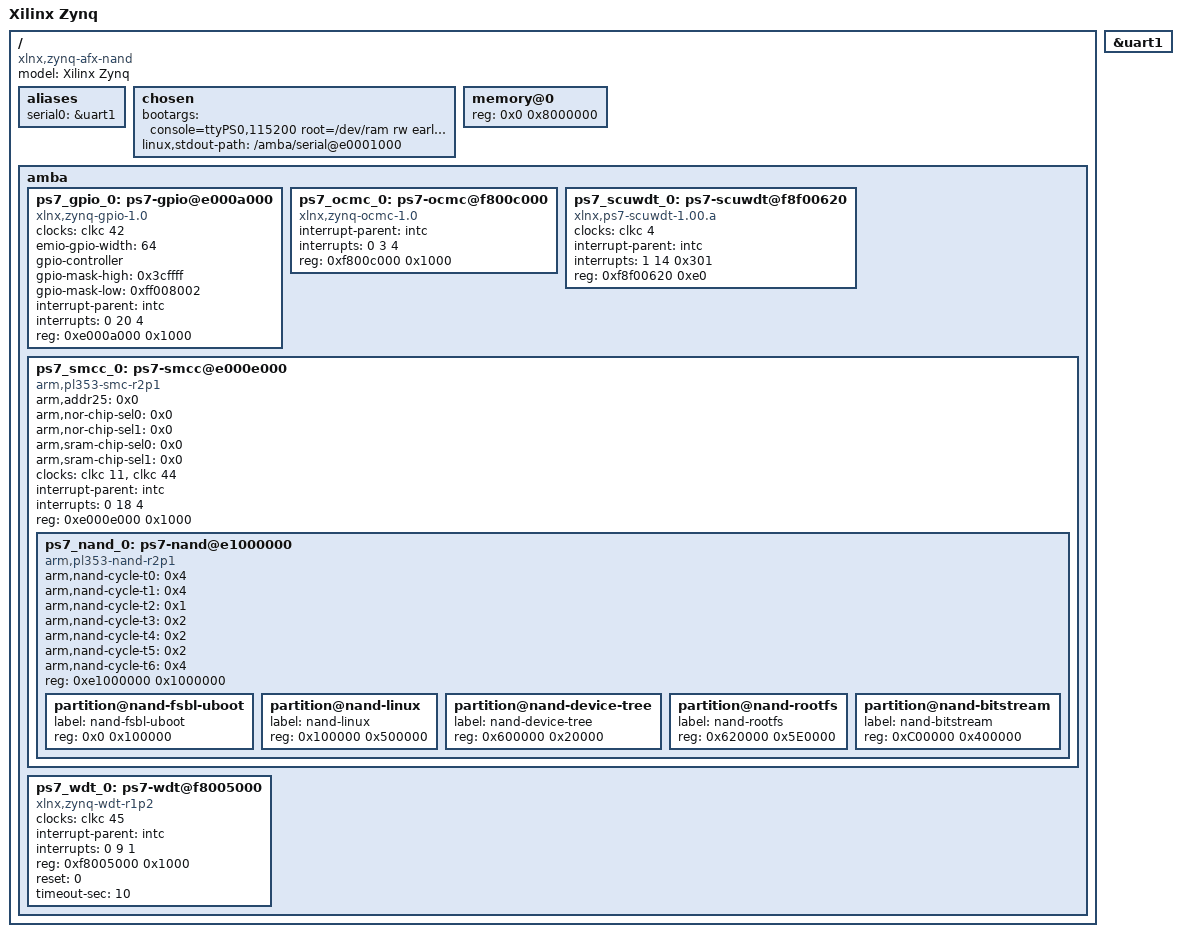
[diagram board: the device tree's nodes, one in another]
/*
 * Device Tree Generator version: 1.1
 *
 * (C) Copyright 2007-2013 Xilinx, Inc.
 * (C) Copyright 2007-2013 Michal Simek
 * (C) Copyright 2007-2012 PetaLogix Qld Pty Ltd
 *
 * Michal SIMEK <monstr@monstr.eu>
 *
 * CAUTION: This file is automatically generated by libgen.
 * Version: Xilinx EDK 14.5 EDK_P.58f
 *
 */
/dts-v1/;
/include/ "zynq-7000.dtsi"

/ {
	compatible = "xlnx,zynq-afx-nand", "xlnx,zynq-7000";
	model = "Xilinx Zynq";

	aliases {
		serial0 = &uart1;
	};

	chosen {
		bootargs = "console=ttyPS0,115200 root=/dev/ram rw earlyprintk";
		linux,stdout-path = "/amba/serial@e0001000";
	};

	memory@0 {
		device_type = "memory";
		reg = <0x0 0x8000000>;
	};

	amba {
		ps7_gpio_0: ps7-gpio@e000a000 {
			#gpio-cells = <2>;
			clocks = <&clkc 42>;
			compatible = "xlnx,zynq-gpio-1.0";
			emio-gpio-width = <64>;
			gpio-controller ;
			gpio-mask-high = <0x3cffff>;
			gpio-mask-low = <0xff008002>;
			interrupt-parent = <&intc>;
			interrupts = <0 20 4>;
			reg = <0xe000a000 0x1000>;
		} ;
		ps7_ocmc_0: ps7-ocmc@f800c000 {
			compatible = "xlnx,zynq-ocmc-1.0";
			interrupt-parent = <&intc>;
			interrupts = <0 3 4>;
			reg = <0xf800c000 0x1000>;
		} ;
		ps7_scuwdt_0: ps7-scuwdt@f8f00620 {
			clocks = <&clkc 4>;
			compatible = "xlnx,ps7-scuwdt-1.00.a";
			device_type = "watchdog";
			interrupt-parent = <&intc>;
			interrupts = <1 14 0x301>;
			reg = <0xf8f00620 0xe0>;
		} ;
		ps7_smcc_0: ps7-smcc@e000e000 {
			#address-cells = <1>;
			#size-cells = <1>;
			arm,addr25 = <0x0>;
			arm,nor-chip-sel0 = <0x0>;
			arm,nor-chip-sel1 = <0x0>;
			arm,sram-chip-sel0 = <0x0>;
			arm,sram-chip-sel1 = <0x0>;
			clock-names = "memclk", "aclk";
			clocks = <&clkc 11>, <&clkc 44>;
			compatible = "arm,pl353-smc-r2p1";
			interrupt-parent = <&intc>;
			interrupts = <0 18 4>;
			ranges ;
			reg = <0xe000e000 0x1000>;
			ps7_nand_0: ps7-nand@e1000000 {
				arm,nand-cycle-t0 = <0x4>;
				arm,nand-cycle-t1 = <0x4>;
				arm,nand-cycle-t2 = <0x1>;
				arm,nand-cycle-t3 = <0x2>;
				arm,nand-cycle-t4 = <0x2>;
				arm,nand-cycle-t5 = <0x2>;
				arm,nand-cycle-t6 = <0x4>;
				compatible = "arm,pl353-nand-r2p1";
				reg = <0xe1000000 0x1000000>;
				#address-cells = <0x1>;
				#size-cells = <0x1>;

				partition@nand-fsbl-uboot {
					label = "nand-fsbl-uboot";
					reg = <0x0 0x100000>;
				};
				partition@nand-linux {
					label = "nand-linux";
					reg = <0x100000 0x500000>;
				};
				partition@nand-device-tree {
					label = "nand-device-tree";
					reg = <0x600000 0x20000>;
				};
				partition@nand-rootfs {
					label = "nand-rootfs";
					reg = <0x620000 0x5E0000>;
				};
				partition@nand-bitstream {
					label = "nand-bitstream";
					reg = <0xC00000 0x400000>;

				};
			} ;
		} ;
		ps7_wdt_0: ps7-wdt@f8005000 {
			clocks = <&clkc 45>;
			compatible = "xlnx,zynq-wdt-r1p2";
			device_type = "watchdog";
			interrupt-parent = <&intc>;
			interrupts = <0 9 1>;
			reg = <0xf8005000 0x1000>;
			reset = <0>;
			timeout-sec = <10>;
		} ;
	};
};

&uart1 {
	status = "okay";
};
